# STM32G553 register map
File version: 2.0.0
CPU: CM33 r0p4, little endian, MPU, FPU, 4 interrupt priority bits
Registers are 32-bit, read-write, reset 0x0 unless marked. A register's access mark holds for its fields unless they carry their own. Offsets are from the block's base; [hi:lo] are bit positions; {n}, {i} and the like mark numbered series; 'fields as' and 'values as' point back to an identical list.

## PLAY1 — PLAY register block
Base 0x40011400
Same registers: PLAY1_S 0x50011400
0x00 PLAY_CFGCR reset 0x1 — PLAY configuration control register
  [0] UNLOCK — Unlock configuration
    0=Configuration is locked. All configuration registers are write protected.; 1=Configuration is unlocked. Configuration registers can be programmed.
0x04 PLAY_SECCFGR — PLAY security attributes configuration register
  [1:0] SEC — Secure access control
    0=All registers are accessible in nonsecure or secure state; 1=Configuration registers can only be accessed in secure state. All other registers can be accessed in secure or nonsecure state.
0x08 PLAY_PRIVCFGR — PLAY privilege attributes configuration register
  [1:0] PRIV — Privilege access control
    0=All registers are accessible in unprivileged or privileged state; 1=Configuration registers can only be accessed in privileged state. All other registers can be accessed in privileged or unprivileged state.
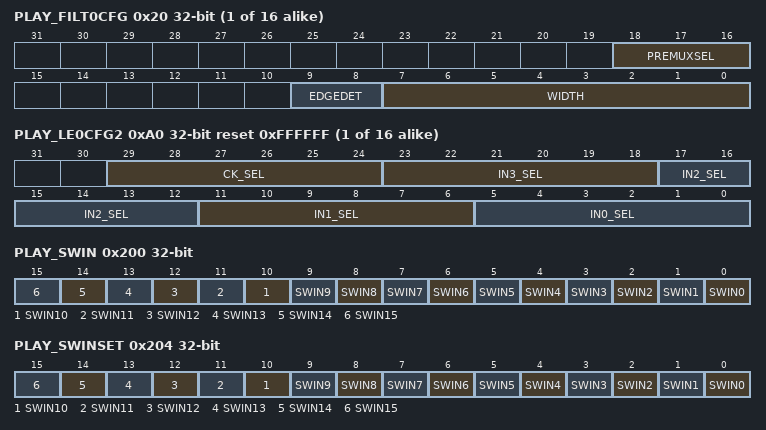
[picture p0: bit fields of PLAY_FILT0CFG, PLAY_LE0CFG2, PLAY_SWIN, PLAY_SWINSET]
{0x20+4i} PLAY_FILT{i}CFG (i=0..15) — PLAY filter {i} configuration register
  [18:16] PREMUXSEL — Input pre-multiplexer select
  [9:8] EDGEDET — Edge detection mode.
    0=Edge detection is bypassed; 1=A rising edge transition on the input is converted into a positive pulse of 1 play_clk cycle
  [7:0] WIDTH — Minimum pulse width
    0=Filter is bypassed
{0x60+4i} PLAY_LE{i}CFG1 (i=0..15) — PLAY logic element {i} configuration register 1
  [15:0] LUT — Look-up table contents.
{0xA0+4i} PLAY_LE{i}CFG2 reset 0xFFFFFF (i=0..15) — PLAY logic element {i} configuration register 2
  [29:24] CK_SEL — Clock enable selection
  [6n+5:6n] IN{n}_SEL (n=0..3) — Logic element input {n} selection
{0x100+4i} PLAY_OUT{i}CFG (i=0..15) — PLAY output {i} configuration register
  [4:0] SEL — Output source selection.
0x200 PLAY_SWIN — PLAY software input status register
  [all] fields
    0=Input low; 1=Input high
  [n] SWIN{n} (n=0..15) — Input swiny state
0x204 PLAY_SWINSET wo — PLAY software input set register
  [all] fields
    0=Input low; 1=Input high
  [n] SWIN{n} (n=0..15) — Set PLAY_SWIN.SWINy
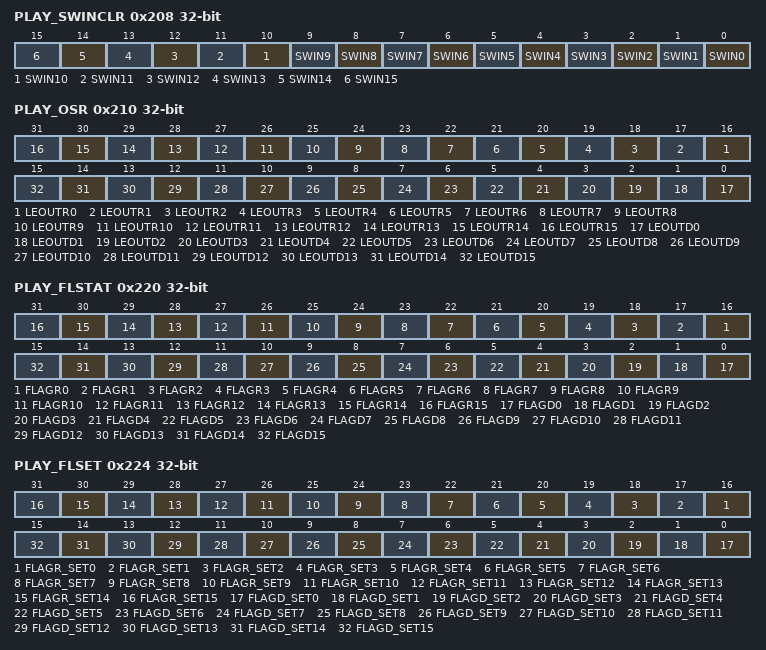
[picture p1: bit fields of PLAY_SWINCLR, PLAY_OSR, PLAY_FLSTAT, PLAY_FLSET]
0x208 PLAY_SWINCLR wo — PLAY software input clear register
  [all] fields
    0=Input low; 1=Input high
  [n] SWIN{n} (n=0..15) — Reset PLAY_SWIN.SWINy
0x210 PLAY_OSR ro — PLAY output status register
  [n+16] LEOUTR{n} (n=0..15) — State of LE registered output leoutry
  [n] LEOUTD{n} (n=0..15) — State of LE direct outputs leoutdy
0x220 PLAY_FLSTAT ro — PLAY flag status register
  [all] fields
    0=Flag reset; 1=Flag set
  [n+16] FLAGR{n} (n=0..15) — Flag state for LEy registered output
  [n] FLAGD{n} (n=0..15) — Flag state for LEy direct output
0x224 PLAY_FLSET wo — PLAY flag set register
  [all] fields
    0=No effect; 1=Set flag
  [n+16] FLAGR_SET{n} (n=0..15) — Flag set for LEy registered output
  [n] FLAGD_SET{n} (n=0..15) — Flag set for LEy direct output
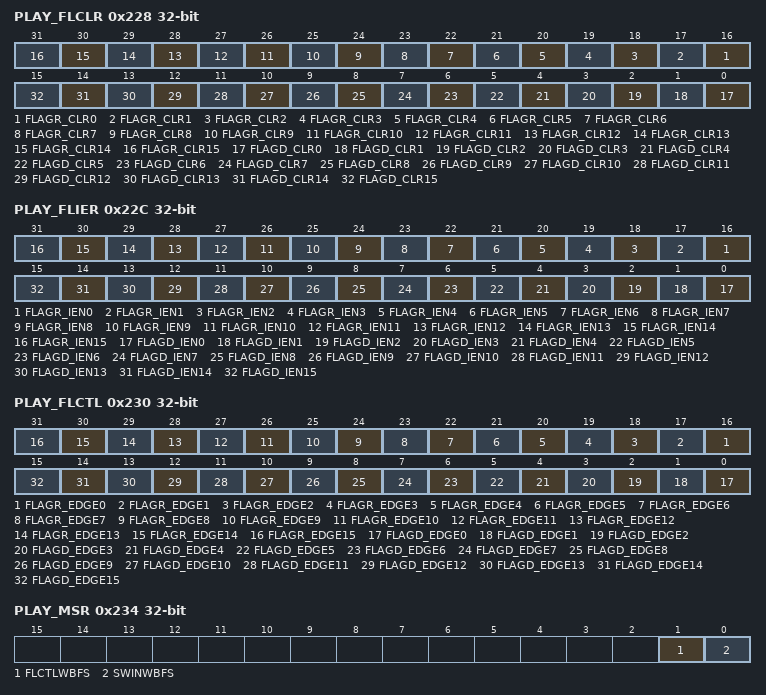
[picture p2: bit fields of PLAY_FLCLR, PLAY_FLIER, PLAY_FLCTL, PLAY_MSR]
0x228 PLAY_FLCLR wo — PLAY flag clear register
  [all] fields
    0=No effect; 1=Clear flag
  [n+16] FLAGR_CLR{n} (n=0..15) — Flag clear for LEy registered output
  [n] FLAGD_CLR{n} (n=0..15) — Flag clear for LEy direct output
0x22C PLAY_FLIER — PLAY flag interrupt enable register
  [n+16] FLAGR_IEN{n} (n=0..15) — Flag interrupt enable for LEy registered output
    0=No interrupt is generated on play_irq; 1=An interrupt is generated on play_irq if PLAY_FLSTAT.FLAGRy = 1
  [n] FLAGD_IEN{n} (n=0..15) — Flag interrupt enable for LEy direct output
    0=No interrupt is generated on play_irq; 1=An interrupt is generated on play_irq if PLAY_FLSTAT.FLAGDy = 1
0x230 PLAY_FLCTL — PLAY flag control register
  [n+16] FLAGR_EDGE{n} (n=0..15) — Edge direction for LEy registered output
    0=FLAGRy is set by a falling edge on leoutry; 1=FLAGRy is set by a rising edge on leoutry
  [n] FLAGD_EDGE{n} (n=0..15) — Edge direction for LEy direct output
    0=FLAGDy is set by a falling edge on leoutdy; 1=FLAGDy is set by a rising edge on leoutdy
0x234 PLAY_MSR ro — PLAY miscellaneous status register
  [1] FLCTLWBFS — PLAY_FLCTL register write busy flag status
    0=PLAY_FLCTL register can be written; 1=Write is pending, any new write access to PLAY_FLCTL register is ignored
  [0] SWINWBFS — PLAY_SWIN register write busy flag status
    0=PLAY_SWIN register can be written; 1=Write is pending, any new write access to PLAY_SWIN, PLAY_SWINCLR or PLAY_SWINSET registers is ignored
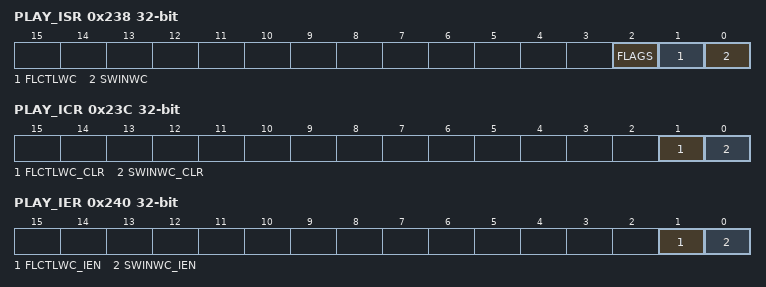
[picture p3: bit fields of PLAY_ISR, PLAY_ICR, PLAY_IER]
0x238 PLAY_ISR ro — PLAY interrupt status register
  [2] FLAGS — Flag interrupts status
    0=No flag interrupts active; 1=One or more bits in PLAY_FLSTAT register is active and has generated an interrupt request
  [1] FLCTLWC — PLAY_FLCTL register write complete interrupt status
    0=Interrupt request is not pending; 1=Interrupt request is pending
  [0] SWINWC — PLAY_SWIN register write complete interrupt status
    values as FLCTLWC
0x23C PLAY_ICR wo reset not defined — PLAY interrupt clear register
  [1] FLCTLWC_CLR — PLAY_FLCTL register write complete interrupt clear
    0=No action; 1=Clear interrupt request
  [0] SWINWC_CLR — PLAY_SWIN register write complete interrupt clear
    0=No action; 1=Clear interrupt request
0x240 PLAY_IER — PLAY interrupt enable register
  [1] FLCTLWC_IEN — PLAY_FLCTL register write complete interrupt enable
    0=Interrupt disabled; 1=Interrupt enabled. An interrupt is generated when a write to the PLAY_FCTL register completes
  [0] SWINWC_IEN — PLAY_SWIN register write complete interrupt enable
    0=Interrupt disabled; 1=Interrupt enabled. An interrupt is generated when a write to the PLAY_SWIN register completes
